# VTM_VTM_CFG1_00B00000h register map
Vendor: Texas Instruments
Peripheral module from a debugger description file (folder AM275x).
Registers are 32-bit, access not given, reset 0x0 unless marked. A register's access mark holds for its fields unless they carry their own. Offsets are as the file gives them; lines under a group give offsets from that group; [hi:lo] are bit positions; {n}, {i} and the like mark numbered series; 'fields as' and 'values as' point back to an identical list; <NAME> marks a mode.

## VTM_CFG1
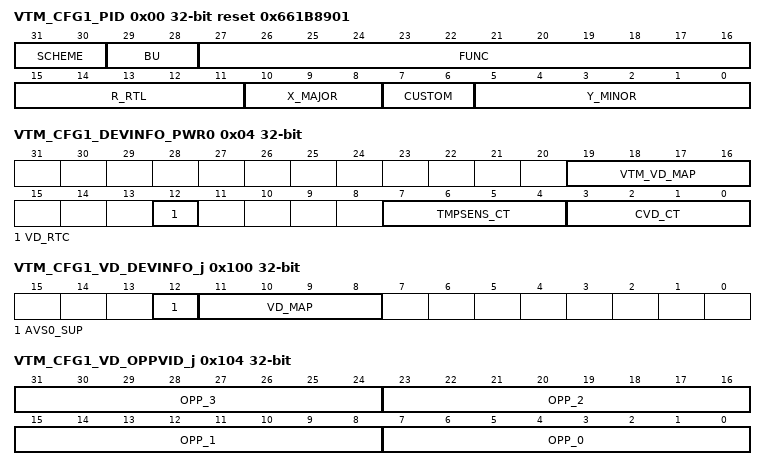
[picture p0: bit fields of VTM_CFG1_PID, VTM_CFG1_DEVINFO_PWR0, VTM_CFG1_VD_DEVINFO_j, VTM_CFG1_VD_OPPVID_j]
0x00 VTM_CFG1_PID ro reset 0x661B8901 — VTM Peripheral Identification Register
  [31:30] SCHEME — PID follows new scheme Reset Source: mod_g_rst_n
  [29:28] BU — Business unit - Processors Reset Source: mod_g_rst_n
  [27:16] FUNC — Module functional identifier - CTRL MMR Reset Source: mod_g_rst_n
  [15:11] R_RTL — RTL revision number - actual value determined by RTL Reset Source: mod_g_rst_n
  [10:8] X_MAJOR — Major revision number - actual value determined by RTL Reset Source: mod_g_rst_n
  [7:6] CUSTOM — Custom revision number - actual value determined by RTL Reset Source: mod_g_rst_n
  [5:0] Y_MINOR — Minor revision number - actual value determined by RTL Reset Source: mod_g_rst_n
0x04 VTM_CFG1_DEVINFO_PWR0 ro — Device specific voltage domain and temp sensor information register.
  [19:16] VTM_VD_MAP — Core voltage domain, cVD, global mapping 4-bit code, in the context of this SOC. It shows in which cVD this VTM is instantiated/placed. This field indicates in which core voltage domain, cVD, has been physically placed this VTM. Valid values: 0x0 to 0xE where: 0x0 = VD_RTC, not present is some SOCs, 0x1 = VD_WKUP, 0x2 = VD_MCU, 0x3 = VD_CORE, not present is some SOCs, 0x4-0xE = Mapping varies between SOCs, 0xF = not implemented. Reset value is a VTM tieoff, d_vtm_vd_map. Reset Source: mod_g_rst_n
  [12] VD_RTC — RTC voltage domain presence. 0: There is NO VD_RTC in this SOC. 1: There is a VD_RTC in this SOC. Reset value is a VTM tieoff, d_vd_rtc. Reset Source: mod_g_rst_n
  [7:4] TMPSENS_CT — Number of temperature sensors associated with this VTM. Valid values are 4'h0 - 4'h8. 0x0: NO temp-sensor associated to this VTM. 0x8: 8 temp-sensors associated to this VTM. 0x9 to 0xF: invalid values. Reset value is a VTM tieoff, d_vtm_tmpsens_ct. Reset Source: mod_g_rst_n
  [3:0] CVD_CT — Number of core voltage domains in device. VD0 is always allocated to VD_RTC, if it exists, and VD1 always to VD_WKUP. The maximum number of cVDs in an SOC is 15, 0xF. Reset value is a VTM tieoff, d_device_cvd_ct. Reset Source: mod_g_rst_n
0x100 VTM_CFG1_VD_DEVINFO_j access per field — Voltage domain a information register. The default reset values will not be necessarily overwritten. The write capability in the MMR is for having the option to debug and have software driven adjustments if necessary.
  [12] AVS0_SUP rw — Indicates VD0 AVS class0 support. Indicates if the cVD associated with this VTM's VD MMR supports AVS-Class0: 0: No AVS-Class0. 1: Supports-AVS-Class0. Reset value is from e-fuse at module (POR) reset, efuse_vd[j]_avs_sup. Reset Source: mod_g_rst_n
  [11:8] VD_MAP ro — Indicates the core voltage domain mapping of VTM VD. Device specific field. This field indicates to which SOC cVD is this VD of this VTM map to. Valid values: 0x0 to 0xE where: 0x0 = VD_RTC, not present is some SOCs, 0x1 = VD_WKUP, 0x2 = VD_MCU, 0x3 = VD_CORE, not present is some SOCs, 0x4-0xE = Mapping varies between SOCs, 0xF = not implemented. Reset value is a VTM tieoff, d_vd[j]_vd_map_ipcfg (technically a direct connection, not latched, so reset agnostic). Reset Source: mod_g_rst_n
0x104 VTM_CFG1_VD_OPPVID_j rw — Voltage domain a VID actual code used as reference by Firmware to set the various voltage domain supply voltages. Reset defaults are sourced from efuse for each OPP. The default reset values will not be necessarily overwritten. The write capability in the MMR is for having the option to debug and have software driven adjustments if necessary.
  [8n+7:8n] OPP_{n} (n=0..3) — OPP {n} default VID. VID code that represents the required VD value in this Voltage domain to operate at. Valid values are from 0x1e to 0x91. Any value outside that range indicates not implemented including 0x0. This is SOC and device/chip specific. Reset value is from e-fuse at POR, efuse_vd[j]_opp_{n}. Reset Source: mod_por_rst_n
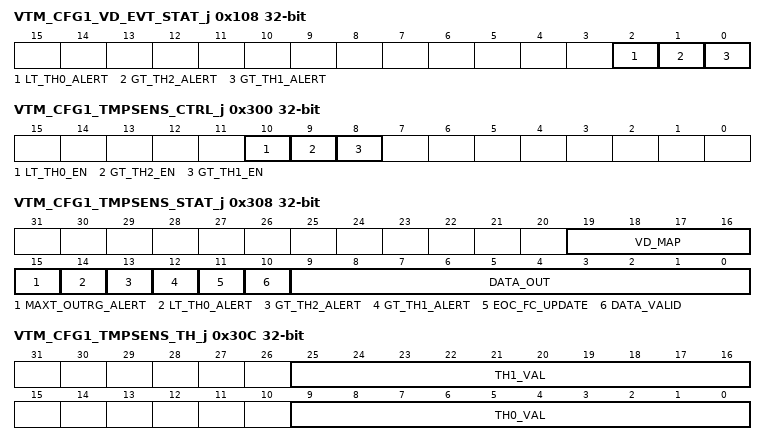
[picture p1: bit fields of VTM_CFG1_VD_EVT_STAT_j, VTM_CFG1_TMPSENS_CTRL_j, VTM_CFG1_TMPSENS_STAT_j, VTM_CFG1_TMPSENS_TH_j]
0x108 VTM_CFG1_VD_EVT_STAT_j ro — Voltage domain a event and control status register.
  [2] LT_TH0_ALERT — This bit reflects the status of the TH0 undertemp alert resulting from the OR of all the similar alerts produced by the temp sensors selected by VTM_VD[j]_EVT_SEL_SET.tsens_evt_sel. Reset Source: mod_g_rst_n
  [1] GT_TH2_ALERT — This bit reflects the status of the merged temperature alert resulting from the combination of all the similar alerts produced by the temp-monitors selected as showed in field VTM_VD[j]_EVT_SEL_SET.tsens_evt_sel. This field shows the actual present level of the resulting OR function of the combined selected signals. Reset Source: mod_g_rst_n
  [0] GT_TH1_ALERT — This bit reflects the status of the merged temperature alert resulting from the OR of all the similar alerts produced by the temp-monitors selected as showed in field VTM_VD[j]_EVT_SEL_SET.tsens_evt_sel. This field shows the actual present value of the resulting OR function of the combined selected signals. Reset Source: mod_g_rst_n
0x10C VTM_CFG1_VD_EVT_SET_j — Voltage domain a event select and control set register. NOTE: This MMR and the companion MMR VTM_VD[a]_EVT_SEL_CLR are linked, which means that they are in fact a single common MMR, with 2 different write addresses/mechanisms, and thus the single common MMR updates with the writes to either MMR and reads to either of these 2 MMRs read the same content.
  [23:16] TSENS_EVT_SEL — In this field we select which of the event contributions of the 8-maximum possible temp-monitors controlled by this VTM will contribute to generate the merged event/alerts of this VD. Any combination of them could be selected and varies between SOCs and VDs. Eg: 0x00 : No temp-monitor event contributes to generate the temperature events of this VD. 0x06: Temp-monitors[2,1] contribute to generate the temperature events of this VD. ... 0xFF: All 8 temp-monitors contribute to generate the temperature events of this VD. 0: Writing 0 to this field produces no effect. 1: Writing 1 to any of the bits in this field sets to 1 the corresponding bit in that field. Reset Source: mod_g_rst_n (access R/W1TS)
0x110 VTM_CFG1_VD_EVT_CLR_j — Voltage domain a event select and control clear register. NOTE: This MMR and the companion MMR VTM_VD[a]_EVT_SEL_SET are linked, which means that they are in fact a single common MMR, with 2 different write addresses/mechanisms, and thus the single common MMR updates with the writes to either MMR and reads to either of these 2 MMRs read the same content.
  [23:16] TSENS_EVT_SEL — In this field we select which of the event contributions of the 8-maximum possible temp-monitors controlled by this VTM will contribute to generate the merged event/alerts of this VD. Any combination of them could be selected and varies between SOCs and VDs. Eg: 0x00 : No temp-monitor event contributes to generate the temperature events of this VD. 0x06: Temp-monitors[2,1] contribute to generate the temperature events of this VD. ... 0xFF: All 8 temp-monitors contribute to generate the temperature events of this VD. 0: Writing 0 to this field produces no effect. 1: Writing 1 to any of the bits in this field clears, = 0, the corresponding bit in that field. Reset Source: mod_g_rst_n (access R/W1TC)
0x204 VTM_CFG1_GT_TH1_INT_RAW_STAT_SET — Interrupt RAW event status and set MMR for interrupt GT_TH1 for each voltage domain. NOTE: This MMR and the companion MMR, VTM_GT_TH1_INT_EN_STAT_CLR are fully linked for write operation, but partially linked for reads, which means that they are in fact a single common MMR, with 2 different write addresses/mechanisms, and thus the single common MMR updates with the writes to either MMR. However the reads to these 2 MMRs don't yield the same read data. Reads to *_INT_RAW_STAT_SET return the full 'raw' events contents of the common linked MMR, whereas reads to MMR *_INT_EN_STAT_CLR will yield the masked-content of the linked MMR. The mask for the read is defined by the contents of the related MMR *_INT_EN_SET/CLR.
  [7:0] INT_VD — Interrupt pending bit set for gt_th1_int from VD[7:0]. Write-operation: 0: Nothing happens. 1: Causes the interrupt flag to be set. Used to manually force/drive an interrupt pending event. Reads return the pending stats regardless of the corresponding enable setting. Reset Source: mod_g_rst_n (access R/W1TS)
0x208 VTM_CFG1_GT_TH1_INT_EN_STAT_CLR — Enabled interrupt event status and clear MMR for interrupt GT_TH1 per voltage domain. NOTE: This MMR and the companion MMR, VTM_GT_TH1_INT_RAW_STAT_SET are fully linked for write operation, but partially linked for reads, which means that they are in fact a single common MMR, with 2 different write addresses/mechanisms, and thus the single common MMR updates with the writes to either MMR. However the reads to these 2 MMRs don't yield the same read data. Reads to *_INT_RAW_STAT_SET return the full 'raw' events contents of the common linked MMR, whereas reads to MMR *_INT_EN_STAT_CLR will yield the masked-content of the linked MMR. The mask for the read is defined by the contents of the related MMR *_INT_EN_SET/CLR.
  [7:0] INT_VD — Interrupt masked pending bit for gt_th1_int from VD[7:0]. Write-operation: 0: Nothing happens. 1: Causes the pending bit to be cleared. Reads return the enabled pending status that includes the corresponding enable setting. Reset Source: mod_g_rst_n (access R/W1TC)
0x214 VTM_CFG1_GT_TH1_INT_EN_SET — Enable set MMR for interrupt GT_TH1 for each voltage domain. NOTE: This MMR and the companion MMR, VTM_GT_TH1_INT_EN_CLR are linked, which means that they are in fact a single common MMR, with 2 different write addresses/mechanisms, and thus the single common MMR updates with the writes to either MMR and reads to either of these 2 MMRs read the same content.
  [7:0] INT_VD — Interrupt enable bit for gt_th1_int from VD[7:0]. Write-operation: 0: Nothing happens. 1: Causes the bit to be set to 1. Reads return the enable settings. Reset Source: mod_g_rst_n (access R/W1TS)
0x218 VTM_CFG1_GT_TH1_INT_EN_CLR — Enable clear MMR for interrupt GT_TH1 for each voltage domain. NOTE: This MMR and the companion MMR, VTM_GT_TH1_INT_EN_SET are linked, which means that they are in fact a single common MMR, with 2 different write addresses/mechanisms, and thus the single common MMR updates with the writes to either MMR and reads to either of these 2 MMRs read the same content.
  [7:0] INT_VD — Interrupt enable bit for gt_th1_int from VD[7:0]. Write-operation: 0: Nothing happens. 1: Causes the bit to be cleared. Reads return the enable settings. Reset Source: mod_g_rst_n (access R/W1TC)
0x224 VTM_CFG1_GT_TH2_INT_RAW_STAT_SET — Interrupt RAW event status and set MMR for interrupt GT_TH2 for each voltage domain. NOTE: This MMR and the companion MMR, VTM_GT_TH2_INT_EN_STAT_CLR are fully linked for write operation, but partially linked for reads, which means that they are in fact a single common MMR, with 2 different write addresses/mechanisms, and thus the single common MMR updates with the writes to either MMR. However the reads to these 2 MMRs don't yield the same read data. Reads to *_INT_RAW_STAT_SET return the full 'raw' events contents of the common linked MMR, whereas reads to MMR *_INT_EN_STAT_CLR will yield the masked-content of the linked MMR. The mask for the read is defined by the contents of the related MMR *_INT_EN_SET/CLR.
  [7:0] INT_VD — Interrupt pending bit set for gt_th2_int from VD[7:0]. Write-operation: 0: Nothing happens. 1: Causes the interrupt flag to be set. Used to manually force/drive an interrupt pending event. Reads return the pending status regardless of the enable setting. Reset Source: mod_g_rst_n (access R/W1TS)
0x228 VTM_CFG1_GT_TH2_INT_EN_STAT_CLR — Enabled interrupt event status and clear MMR for interrupt GT_TH2 per voltage domain. NOTE: This MMR and the companion MMR, VTM_GT_TH2_INT_RAW_STAT_SET are fully linked for write operation, but partially linked for reads, which means that they are in fact a single common MMR, with 2 different write addresses/mechanisms, and thus the single common MMR updates with the writes to either MMR. However the reads to these 2 MMRs don't yield the same read data. Reads to *_INT_RAW_STAT_SET return the full 'raw' events contents of the common linked MMR, whereas reads to MMR *_INT_EN_STAT_CLR will yield the masked-content of the linked MMR. The mask for the read is defined by the contents of the related MMR *_INT_EN_SET/CLR.
  [7:0] INT_VD — Interrupt enabled pending bit for gt_th2_int from VD[7:0]. Write-operation: 0: Nothing happens. 1: Causes the pending bit to be cleared. Reads return the enabled pending status including the corresponding enable setting. Reset Source: mod_g_rst_n (access R/W1TC)
0x234 VTM_CFG1_GT_TH2_INT_EN_SET — Enable set MMR for interrupt GT_TH2 for each voltage domain. NOTE: This MMR and the companion MMR, VTM_GT_TH2_INT_EN_CLR are linked, which means that they are in fact a single common MMR, with 2 different write addresses/mechanisms, and thus the single common MMR updates with the writes to either MMR and reads to either of these 2 MMRs read the same content.
  [7:0] INT_VD — Interrupt enable bit for gt_th2_int from VD[7:0]. Write-operation: 0: Nothing happens. 1: Causes the bit to be set to 1. Reads return the enable settings. Reset Source: mod_g_rst_n (access R/W1TS)
0x238 VTM_CFG1_GT_TH2_INT_EN_CLR — Enable clear MMR for interrupt GT_TH2 for each voltage domain. NOTE: This MMR and the companion MMR, VTM_GT_TH2_INT_EN_SET are linked, which means that they are in fact a single common MMR, with 2 different write addresses/mechanisms, and thus the single common MMR updates with the writes to either MMR and reads to either of these 2 MMRs read the same content.
  [7:0] INT_VD — Interrupt enable bit for gt_th2_int from VD[7:0]. Write-operation: 0: Nothing happens. 1: Causes the bit to be cleared. Reads return the enable settings. Reset Source: mod_g_rst_n (access R/W1TC)
0x244 VTM_CFG1_LT_TH0_INT_RAW_STAT_SET — Interrupt RAW event status and set MMR for interrupt LT_TH0 for each voltage domain. NOTE: This MMR and the companion MMR, VTM_LT_TH0_INT_EN_STAT_CLR are fully linked for write operation, but partially linked for reads, which means that they are in fact a single common MMR, with 2 different write addresses/mechanisms, and thus the single common MMR updates with the writes to either MMR. However the reads to these 2 MMRs don't yield the same read data. Reads to *_INT_RAW_STAT_SET return the full 'raw' events contents of the common linked MMR, whereas reads to MMR *_INT_EN_STAT_CLR will yield the masked-content of the linked MMR. The mask for the read is defined by the contents of the related MMR *_INT_EN_SET/CLR.
  [7:0] INT_VD — Interrupt pending bit set for lt_th0_int from VD[7:0]. Write-operation: 0: Nothing happens. 1: Causes the interrupt flag to be set. Used to manually force/drive an interrupt pending event. Reads return the raw pending status regardless of the corresponding enable setting. Reset Source: mod_g_rst_n (access R/W1TS)
0x248 VTM_CFG1_LT_TH0_INT_EN_STAT_CLR — Enabled interrupt event status and clear MMR for interrupt LT_TH0 per voltage domain. NOTE: This MMR and the companion MMR, VTM_LT_TH0_INT_RAW_STAT_SET are fully linked for write operation, but partially linked for reads, which means that they are in fact a single common MMR, with 2 different write addresses/mechanisms, and thus the single common MMR updates with the writes to either MMR. However the reads to these 2 MMRs don't yield the same read data. Reads to *_INT_RAW_STAT_SET return the full 'raw' events contents of the common linked MMR, whereas reads to MMR *_INT_EN_STAT_CLR will yield the masked-content of the linked MMR. The mask for the read is defined by the contents of the related MMR *_INT_EN_SET/CLR.
  [7:0] INT_VD — Interrupt enabled pending status bit for lt_th0_int from VD[7:0]. Write-operation: 0: Nothing happens. 1: Causes the pending bit to be cleared. Reads return the enabled pending status that factors in the corresponding enable along with the pending status. Reset Source: mod_g_rst_n (access R/W1TC)
0x254 VTM_CFG1_LT_TH0_INT_EN_SET — Enable set MMR for interrupt LT_TH0 for each voltage domain. NOTE: This MMR and the companion MMR, VTM_LT_TH0_INT_EN_CLR are linked, which means that they are in fact a single common MMR, with 2 different write addresses/mechanisms, and thus the single common MMR updates with the writes to either MMR and reads to either of these 2 MMRs read the same content.
  [7:0] INT_VD — Interrupt enable bit for lt_th0_int from VD[7:0]. Write-operation: 0: Nothing happens. 1: Causes the bit to be set to 1. Reads return the enable settings. Reset Source: mod_g_rst_n (access R/W1TS)
0x258 VTM_CFG1_LT_TH0_INT_EN_CLR — Enable clear MMR for interrupt LT_TH0 for each voltage domain. NOTE: This MMR and the companion MMR, VTM_LT_TH0_INT_EN_SET are linked, which means that they are in fact a single common MMR, with 2 different write addresses/mechanisms, and thus the single common MMR updates with the writes to either MMR and reads to either of these 2 MMRs read the same content.
  [7:0] INT_VD — Interrupt enable bit for lt_th0_int from VD[7:0]. Write-operation: 0: Nothing happens. 1: Causes the bit to be cleared. Reads return the enable settings. Reset Source: mod_g_rst_n (access R/W1TC)
0x300 VTM_CFG1_TMPSENS_CTRL_j rw — Temperature Sensor Band-gap control register for sensor j.
  [10] LT_TH0_EN — Enable under-threshold0 event. Temp event/level control: 0 = Don't generate output level. 1 = Enable generation of event/level high when temperature reading is < value set for threshold point 0. Reset value is POR only. Reset Source: mod_por_rst_n
  [9] GT_TH2_EN — Enable over-threshold2 event. Temp event/level control: 0 = Don't generate output level. 1 = Enable generation of event/level high when temperature reading is > value set for threshold point 2. Reset value is POR only. Reset Source: mod_por_rst_n
  [8] GT_TH1_EN — Enable over-threshold1 event. Temp event/level control: 0 = Don't generate output level. 1 = Enable generation of event/level high when temperature reading is > value set for threshold point 1. Reset value is POR only. Reset Source: mod_por_rst_n
0x308 VTM_CFG1_TMPSENS_STAT_j ro — Temperature Sensor Band-gap Status register for sensor j.
  [19:16] VD_MAP — Indicates the core voltage domain placement of the temp sensor. Device specific field. This field indicates in which core voltage domain, cVD, has been physically placed the temp-monitor. Valid values: 0x0 to 0xE where: 0x0 = VD_RTC, not present is some SOCs, 0x1 = VD_WKUP, 0x2 = VD_MCU, 0x3 = VD_CORE, not present is some SOCs, 0x4-0xE = Mapping varies between SOCs, 0xF = not implemented. Reset value is a VTM tieoff at POR, d_VTM_TMPSENS[j]_STAT_vd_map_ipcfg. Reset Source: mod_por_rst_n
  [15] MAXT_OUTRG_ALERT — This bit will be driven to a level 1 for a given temperature monitor if it has its corresponding bit maxt_outrg_en = 1, and the temperature reading is reporting to be outside the max temperature supported, temp > programmed value. The level of this signal is a reflection, with some clock delays, of the temperature code reading. This is NOT an sticky bit. Reset value is POR only. Reset Source: mod_por_rst_n
  [14] LT_TH0_ALERT — This field reflects the status of the lt_th0_alert comparator result during continuous mode. The control MMR field lt_th0_en = 1 is required for this field to become 1. Reset value is at POR or clrz. Reset Source: mod_por_rst_n
  [13] GT_TH2_ALERT — This field reflects the status of the gt_th2_alert comparator result during continuous mode. The control MMR field gt_th2_en = 1 is required for this field to become 1. Reset value is at POR or clrz. Reset Source: mod_por_rst_n
  [12] GT_TH1_ALERT — This field reflects the status of the gt_th1_alert comparator result during continuous mode. The control MMR field gt_th1_en = 1 is required for this field to become 1. Reset value is at POR or clrz. Reset Source: mod_por_rst_n
  [11] EOC_FC_UPDATE — First time end of conversion. This field is reset to 0 every time VTM.por_rst_n or VTM_TMPSENS[j]_CTRL.clrz are active, or when continuous mode is deasserted. This bit will be set to 1 after the first time after reset release that data_valid transitions from 0 to 1, and remain at 1 until next time either of por_rst_n or VTM_TMPSENS[j]_CTRL.clrz are active, or when continuous mode is deasserted. Reset value is at POR or VTM_TMPSENS[j]_CTRL.clrz, or continuous mode deassertion. Reset Source: mod_por_rst_n
  [10] DATA_VALID — Data_valid signal value from sensor: ADC End of Conversion. End of conversion indicated by 0 to 1 transition. When high data_out(9:0) out of the temp-monitor is valid. This field doesn't reflect the instantaneous output from the temp-monitor. This field gets latched/updated in this VTM register when the data_valid value from temp-monitor toggles. Note the data_valid sensor output is asserted for only a short time window (on the order of a few clock cycles). Reset value is at POR or VTM_TMPSENS[j]_CTRL.clrz. Reset Source: mod_por_rst_n
  [9:0] DATA_OUT — Data_out signal value from sensor: Temperature data from the ADC in monitor. Valid after VTM_TMPSENS[j]_STAT.eoc_fc_update = 1. This value will be latched in this VTM register every time monitor output data_valid transitions from 0 to 1 (specifically one vbus cycle after data_valid asserts). Reset value is POR only. Reset Source: mod_por_rst_n
0x30C VTM_CFG1_TMPSENS_TH_j rw — Temperature Sensor Band-gap Threshold register for sensor j.
  [25:16] TH1_VAL — Threshold point-1, thpt1, temp-value. Is a 10-bit temperature reference value. This is the 10-bit value that represents a high temperature point, as per sensor spec, with which to compare the present temperature reading, same 10-bit format. If the current temperature reading is > th1_val[9:0] and gt_th1_en=1, that will cause the VTM to set the gt_th1_alert output. Once the current temp reading =< th1_val[9:0] then gt_th1_alert output will go to 0. Reset value is at POR only. Reset Source: mod_por_rst_n
  [9:0] TH0_VAL — Threshold point-0, thpt0, temp-value. Is a 10-bit temperature reference value. This is the 10-bit value that represents a high temperature point, as per sensor spec, with which to compare the present temperature reading, same 10-bit format. If the current temperature reading is < th0_val[9:0] and lt_th0_en=1, that will cause the VTM to set the lt_th0_alert output. Once the current temp reading => th0_val[9:0] then lt_th0_alert output will go to 0. Reset value is at POR only. Reset Source: mod_por_rst_n
0x310 VTM_CFG1_TMPSENS_TH2_j rw — Temperature Sensor Band-gap Threshold register 2 for sensor j.
  [9:0] TH2_VAL — Threshold point-2, thpt2, temp-value. Is a 10-bit temperature reference value. This is the 10-bit value that represents a high temperature point, as per sensor spec, with which to compare the present temperature reading, same 10-bit format. If the current temperature reading is > th2_val[9:0] and gt_th2_en=1, that will cause the VTM to set the gt_th2_alert output. Once the current temp reading =< th2_val[9:0] then gt_th2_alert output will go to 0. Reset value is at POR only. Reset Source: mod_por_rst_n
